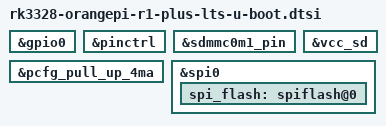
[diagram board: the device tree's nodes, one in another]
// SPDX-License-Identifier: GPL-2.0-or-later
/*
 * (C) Copyright 2018-2019 Rockchip Electronics Co., Ltd
 * (C) Copyright 2020 David Bauer
 */

#include "rk3328-u-boot.dtsi"
#include "rk3328-sdram-lpddr3-666.dtsi"

&gpio0 {
	bootph-pre-ram;
};

&pinctrl {
	bootph-pre-ram;
};

&sdmmc0m1_pin {
	bootph-pre-ram;
};

&pcfg_pull_up_4ma {
	bootph-pre-ram;
};

/* Need this and all the pinctrl/gpio stuff above to set pinmux */
&vcc_sd {
	bootph-pre-ram;
};

&spi0 {
	spi_flash: spiflash@0 {
		bootph-all;
	};
};
